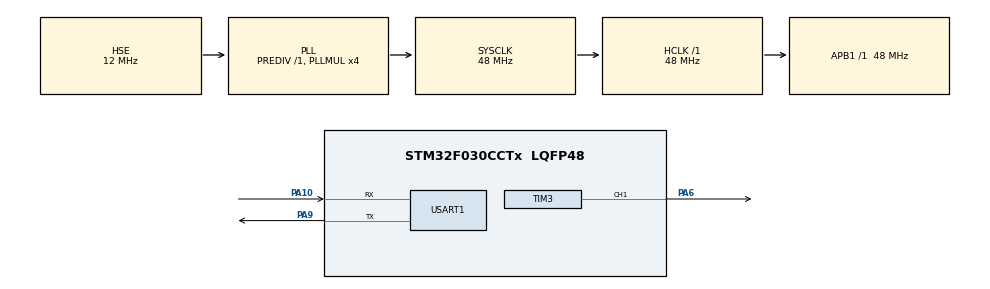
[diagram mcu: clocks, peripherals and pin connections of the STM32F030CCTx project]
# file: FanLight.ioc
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Dma.Request0=TIM3_CH1/TRIG
Dma.Request1=USART1_RX
Dma.Request2=USART1_TX
Dma.TIM3_CH1/TRIG.0.Direction=DMA_MEMORY_TO_PERIPH
Dma.TIM3_CH1/TRIG.0.Instance=DMA1_Channel4
Dma.TIM3_CH1/TRIG.0.MemDataAlignment=DMA_MDATAALIGN_HALFWORD
Dma.TIM3_CH1/TRIG.0.MemInc=DMA_MINC_ENABLE
Dma.TIM3_CH1/TRIG.0.Mode=DMA_NORMAL
Dma.TIM3_CH1/TRIG.0.PeriphDataAlignment=DMA_PDATAALIGN_HALFWORD
Dma.TIM3_CH1/TRIG.0.PeriphInc=DMA_PINC_DISABLE
Dma.TIM3_CH1/TRIG.0.Priority=DMA_PRIORITY_LOW
Dma.USART1_RX.1.Direction=DMA_PERIPH_TO_MEMORY
Dma.USART1_RX.1.Instance=DMA1_Channel1
Dma.USART1_RX.1.MemDataAlignment=DMA_MDATAALIGN_BYTE
Dma.USART1_RX.1.MemInc=DMA_MINC_ENABLE
Dma.USART1_RX.1.Mode=DMA_NORMAL
Dma.USART1_RX.1.PeriphDataAlignment=DMA_PDATAALIGN_BYTE
Dma.USART1_RX.1.PeriphInc=DMA_PINC_DISABLE
Dma.USART1_RX.1.Priority=DMA_PRIORITY_LOW
Dma.USART1_TX.2.Direction=DMA_MEMORY_TO_PERIPH
Dma.USART1_TX.2.Instance=DMA1_Channel2
Dma.USART1_TX.2.MemDataAlignment=DMA_MDATAALIGN_BYTE
Dma.USART1_TX.2.MemInc=DMA_MINC_ENABLE
Dma.USART1_TX.2.Mode=DMA_NORMAL
Dma.USART1_TX.2.PeriphDataAlignment=DMA_PDATAALIGN_BYTE
Dma.USART1_TX.2.PeriphInc=DMA_PINC_DISABLE
Dma.USART1_TX.2.Priority=DMA_PRIORITY_LOW
Mcu.Family=STM32F0
Mcu.Name=STM32F030CCTx
Mcu.Package=LQFP48
NVIC.DMA1_Channel1_IRQn=true\:0\:0\:false\:false\:true\:false\:true\:true
NVIC.DMA1_Channel2_3_IRQn=true\:0\:0\:false\:false\:true\:false\:true\:true
NVIC.DMA1_Channel4_5_IRQn=true\:0\:0\:true\:false\:true\:false\:true\:true
NVIC.TIM15_IRQn=true\:0\:0\:false\:false\:true\:true\:true\:true
NVIC.USART1_IRQn=true\:0\:0\:false\:false\:true\:true\:true\:true
PA10.Mode=Asynchronous
PA10.Signal=USART1_RX
PA13.Mode=Serial_Wire
PA13.Signal=SYS_SWDIO
PA14.Mode=Serial_Wire
PA14.Signal=SYS_SWCLK
PA6.Signal=S_TIM3_CH1
PA9.Mode=Asynchronous
PA9.Signal=USART1_TX
PF0-OSC_IN.Mode=HSE-External-Oscillator
PF0-OSC_IN.Signal=RCC_OSC_IN
PF1-OSC_OUT.Mode=HSE-External-Oscillator
PF1-OSC_OUT.Signal=RCC_OSC_OUT
ProjectManager.HeapSize=0x6400
ProjectManager.StackSize=0x400
ProjectManager.TargetToolchain=Makefile
RCC.AHBFreq_Value=48000000
RCC.APB1Freq_Value=48000000
RCC.APB1TimFreq_Value=48000000
RCC.HCLKFreq_Value=48000000
RCC.HSE_VALUE=12000000
RCC.PLLMUL=RCC_PLL_MUL4
RCC.PLLSourceVirtual=RCC_PLLSOURCE_HSE
RCC.SYSCLKFreq_VALUE=48000000
RCC.SYSCLKSource=RCC_SYSCLKSOURCE_PLLCLK
SH.S_TIM3_CH1.0=TIM3_CH1,PWM Generation1 CH1
TIM15.Period=1000-1
TIM15.Prescaler=48-1
TIM3.Channel-PWM\ Generation1\ CH1=TIM_CHANNEL_1
TIM3.Period=59
TIM6.Prescaler=48-1
USART1.VirtualMode-Asynchronous=VM_ASYNC
VP_TIM15_VS_ClockSourceINT.Mode=Internal
VP_TIM6_VS_ClockSourceINT.Mode=Enable_Timer
board=custom

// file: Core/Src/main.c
/* USER CODE BEGIN Header */
/**
  ******************************************************************************
  * @file           : main.c
  * @brief          : Main program body
  ******************************************************************************
  * @attention
  *
  * Copyright (c) 2021 STMicroelectronics.
  * All rights reserved.
  *
  * This software is licensed under terms that can be found in the LICENSE file
  * in the root directory of this software component.
  * If no LICENSE file comes with this software, it is provided AS-IS.
  *
  ******************************************************************************
  */
/* USER CODE END Header */
#include "main.h"
#include "dma.h"
#include "tim.h"
#include "usart.h"
#include "gpio.h"

/* USER CODE BEGIN Includes */
#include "app.h"
#include "hal.h"
#include "bsp.h"
/* USER CODE END Includes */

void SystemClock_Config(void);

/* USER CODE BEGIN 0 */
uint8_t rx_buffer[256];
/* USER CODE END 0 */

int main(void)
{

  /* MCU Configuration--------------------------------------------------------*/

  /* Reset of all peripherals, Initializes the Flash interface and the Systick. */
  HAL_Init();

  /* Configure the system clock */
  SystemClock_Config();

  /* Initialize all configured peripherals */
  MX_GPIO_Init();
  MX_DMA_Init();
  MX_TIM3_Init();
  MX_TIM15_Init();
  MX_USART1_UART_Init();
  MX_TIM6_Init();
  /* USER CODE BEGIN 2 */
  BSP_Layer_Init();
  HAL_Layer_Init();
  APP_Layer_Init();
  HAL_TIM_Base_Start_IT(&htim15);
  /* USER CODE END 2 */

  /* Infinite loop */
  while (1)
  {

  }
}

void SystemClock_Config(void)
{
  RCC_OscInitTypeDef RCC_OscInitStruct = {0};
  RCC_ClkInitTypeDef RCC_ClkInitStruct = {0};
  RCC_PeriphCLKInitTypeDef PeriphClkInit = {0};

  /** Initializes the RCC Oscillators according to the specified parameters
  * in the RCC_OscInitTypeDef structure.
  */
  RCC_OscInitStruct.OscillatorType = RCC_OSCILLATORTYPE_HSE;
  RCC_OscInitStruct.HSEState = RCC_HSE_ON;
  RCC_OscInitStruct.PLL.PLLState = RCC_PLL_ON;
  RCC_OscInitStruct.PLL.PLLSource = RCC_PLLSOURCE_HSE;
  RCC_OscInitStruct.PLL.PLLMUL = RCC_PLL_MUL4;
  RCC_OscInitStruct.PLL.PREDIV = RCC_PREDIV_DIV1;
  if (HAL_RCC_OscConfig(&RCC_OscInitStruct) != HAL_OK)
  {
    Error_Handler();
  }

  /** Initializes the CPU, AHB and APB buses clocks
  */
  RCC_ClkInitStruct.ClockType = RCC_CLOCKTYPE_HCLK|RCC_CLOCKTYPE_SYSCLK
                              |RCC_CLOCKTYPE_PCLK1;
  RCC_ClkInitStruct.SYSCLKSource = RCC_SYSCLKSOURCE_PLLCLK;
  RCC_ClkInitStruct.AHBCLKDivider = RCC_SYSCLK_DIV1;
  RCC_ClkInitStruct.APB1CLKDivider = RCC_HCLK_DIV1;

  if (HAL_RCC_ClockConfig(&RCC_ClkInitStruct, FLASH_LATENCY_1) != HAL_OK)
  {
    Error_Handler();
  }
  PeriphClkInit.PeriphClockSelection = RCC_PERIPHCLK_USART1;
  PeriphClkInit.Usart1ClockSelection = RCC_USART1CLKSOURCE_PCLK1;
  if (HAL_RCCEx_PeriphCLKConfig(&PeriphClkInit) != HAL_OK)
  {
    Error_Handler();
  }
}

/* USER CODE BEGIN 4 */
void HAL_TIM_PeriodElapsedCallback (TIM_HandleTypeDef * htim)
{
	if (htim == &htim15)
	{
    static int cnt = 0;
    ++cnt;
    if(cnt >= 100){
      APP_Layer_default_loop();
      //printf_log("timer_test!\n");
      cnt = 0;
    }
	}
}
/* USER CODE END 4 */

void Error_Handler(void)
{
  __disable_irq();
  while (1)
  {
  }
}
